VERSION ""

NS_ :

BS_:

BU_: XXX

BO_ 53 ACCELERATOR: 32 XXX
 SG_ CHECKSUM : 0|16@1+ (1,0) [0|65535] "" XXX
 SG_ COUNTER : 16|8@1+ (1,0) [0|255] "" XXX
 SG_ GEAR : 192|3@1+ (1,0) [0|7] "" XXX
 SG_ ACCELERATOR_PEDAL : 40|8@1+ (1,0) [0|255] "" XXX

BO_ 80 LKAS: 16 XXX
 SG_ STEER_REQ : 52|1@1+ (1,0) [0|1] "" XXX
 SG_ TORQUE_REQUEST : 41|11@1+ (1,-1024) [0|4095] "" XXX
 SG_ LKA_ICON : 38|2@1+ (1,0) [0|255] "" XXX
 SG_ NEW_SIGNAL_1 : 27|2@1+ (1,0) [0|255] "" XXX
 SG_ LFA_BUTTON : 56|1@1+ (1,0) [0|255] "" XXX
 SG_ COUNTER : 16|8@1+ (1,0) [0|255] "" XXX
 SG_ CHECKSUM : 0|16@1+ (1,0) [0|65535] "" XXX
 SG_ STEER_MODE : 65|3@1+ (1,0) [0|1] "" XXX
 SG_ LKA_WARNING : 32|1@1+ (1,0) [0|1] "" XXX
 SG_ LKA_ASSIST : 62|1@1+ (1,0) [0|1] "" XXX
 SG_ LKA_MODE : 24|3@1+ (1,0) [0|7] "" XXX
 SG_ NEW_SIGNAL_2 : 70|2@0+ (1,0) [0|3] "" XXX
 SG_ SET_ME_1 : 80|1@0+ (1,0) [0|1] "" XXX
 SG_ NEW_SIGNAL_3 : 111|8@0+ (1,0) [0|255] "" XXX

BO_ 298 LFA: 16 XXX
 SG_ STEER_REQ : 52|1@1+ (1,0) [0|1] "" XXX
 SG_ TORQUE_REQUEST : 41|11@1+ (1,-1024) [0|4095] "" XXX
 SG_ LKA_ICON : 38|2@1+ (1,0) [0|255] "" XXX
 SG_ NEW_SIGNAL_1 : 27|2@1+ (1,0) [0|255] "" XXX
 SG_ LFA_BUTTON : 56|1@1+ (1,0) [0|255] "" XXX
 SG_ COUNTER : 16|8@1+ (1,0) [0|255] "" XXX
 SG_ CHECKSUM : 0|16@1+ (1,0) [0|65535] "" XXX
 SG_ STEER_MODE : 65|3@1+ (1,0) [0|1] "" XXX
 SG_ LKA_WARNING : 32|1@1+ (1,0) [0|1] "" XXX
 SG_ LKA_ASSIST : 62|1@1+ (1,0) [0|1] "" XXX
 SG_ LKA_MODE : 24|3@1+ (1,0) [0|7] "" XXX
 SG_ NEW_SIGNAL_2 : 70|2@0+ (1,0) [0|3] "" XXX
 SG_ SET_ME_1 : 80|1@0+ (1,0) [0|1] "" XXX
 SG_ NEW_SIGNAL_3 : 111|8@0+ (1,0) [0|255] "" XXX

BO_ 96 ESP_STATUS: 32 XXX
 SG_ CHECKSUM : 0|16@1+ (1,0) [0|65535] "" XXX
 SG_ COUNTER : 16|8@1+ (1,0) [0|255] "" XXX
 SG_ ESP_DISABLED : 42|3@1+ (1,0) [0|63] "" XXX

BO_ 101 BRAKE: 32 XXX
 SG_ CHECKSUM : 0|16@1+ (1,0) [0|65535] "" XXX
 SG_ COUNTER : 16|8@1+ (1,0) [0|255] "" XXX
 SG_ BRAKE_PRESSED : 57|1@1+ (1,0) [0|3] "" XXX

BO_ 160 WHEEL_SPEEDS: 24 XXX
 SG_ CHECKSUM : 0|16@1+ (1,0) [0|65535] "" XXX
 SG_ COUNTER : 16|8@1+ (1,0) [0|255] "" XXX
 SG_ WHEEL_SPEED_1 : 64|16@1+ (0.03125,0) [0|65535] "m/s" XXX
 SG_ WHEEL_SPEED_2 : 80|16@1+ (0.03125,0) [0|65535] "m/s" XXX
 SG_ WHEEL_SPEED_3 : 96|16@1+ (0.03125,0) [0|65535] "m/s" XXX
 SG_ WHEEL_SPEED_4 : 112|16@1+ (0.03125,0) [0|65535] "m/s" XXX

BO_ 234 MDPS: 24 XXX
 SG_ CHECKSUM : 0|16@1+ (1,0) [0|65535] "" XXX
 SG_ COUNTER : 16|8@1+ (1,0) [0|255] "" XXX
 SG_ LKA_ACTIVE : 48|1@0+ (1,0) [0|16777215] "" XXX
 SG_ STEERING_OUT_TORQUE : 64|12@1+ (0.1,-204.8) [0|65535] "" XXX
 SG_ STEERING_COL_TORQUE : 80|13@1+ (1,-4095) [0|4095] "" XXX
 SG_ STEERING_ANGLE : 96|16@1- (-0.1,0) [0|255] "deg" XXX
 SG_ STEERING_ANGLE_2 : 128|16@1- (-0.1,0) [0|65535] "deg" XXX

BO_ 293 STEERING_SENSORS: 16 XXX
 SG_ CHECKSUM : 0|16@1+ (1,0) [0|65535] "" XXX
 SG_ COUNTER : 16|8@1+ (1,0) [0|255] "" XXX
 SG_ STEERING_RATE : 40|8@1- (-0.1,0) [0|255] "deg/s" XXX
 SG_ STEERING_ANGLE : 24|16@1- (-0.1,0) [0|255] "deg" XXX

BO_ 373 SCC1: 24 XXX
 SG_ CHECKSUM : 0|16@1+ (1,0) [0|65535] "" XXX
 SG_ COUNTER : 16|8@1+ (1,0) [0|255] "" XXX
 SG_ ACCEL_REQ : 48|13@1- (1,0) [0|1023] "" XXX
 SG_ CRUISE_ACTIVE : 68|1@0+ (1,0) [0|1] "" XXX

BO_ 416 CRUISE_INFO: 32 XXX
 SG_ CHECKSUM : 0|16@1+ (1,0) [0|65535] "" XXX
 SG_ COUNTER : 16|8@1+ (1,0) [0|255] "" XXX
 SG_ CRUISE_STANDSTILL : 76|1@1+ (1,0) [0|1] "" XXX
 SG_ SET_SPEED : 102|7@0+ (1,0) [0|127] "km/h or mph" XXX
 SG_ CRUISE_ACTIVE : 184|1@1+ (1,0) [0|1] "" XXX

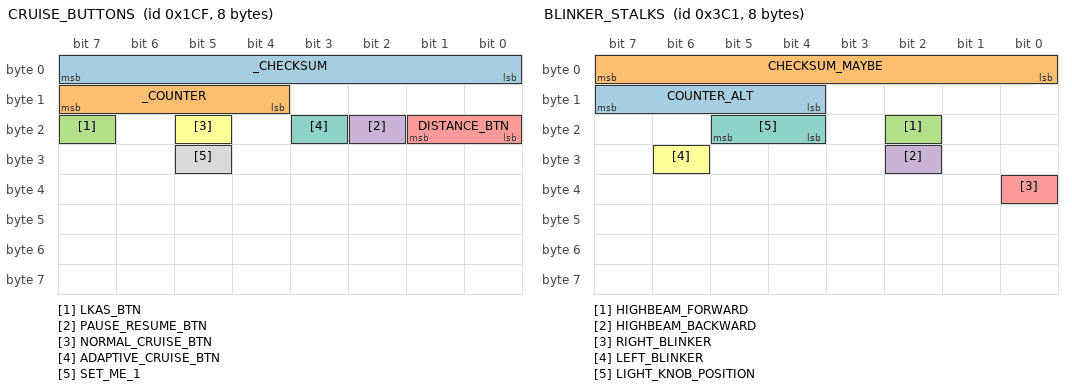
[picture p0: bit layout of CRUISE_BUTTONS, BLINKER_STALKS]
BO_ 463 CRUISE_BUTTONS: 8 XXX
 SG_ _CHECKSUM : 0|8@1+ (1,0) [0|65535] "" XXX
 SG_ _COUNTER : 12|4@1+ (1,0) [0|255] "" XXX
 SG_ LKAS_BTN : 23|1@1+ (1,0) [0|1] "" XXX
 SG_ PAUSE_RESUME_BTN : 18|1@1+ (1,0) [0|1] "" XXX
 SG_ DISTANCE_BTN : 16|2@1+ (1,0) [0|3] "" XXX
 SG_ NORMAL_CRUISE_BTN : 21|1@1+ (1,0) [0|1] "" XXX
 SG_ ADAPTIVE_CRUISE_BTN : 19|1@1+ (1,0) [0|1] "" XXX
 SG_ SET_ME_1 : 29|1@1+ (1,0) [0|1] "" XXX

BO_ 961 BLINKER_STALKS: 8 XXX
 SG_ COUNTER_ALT : 15|4@0+ (1,0) [0|15] "" XXX
 SG_ CHECKSUM_MAYBE : 7|8@0+ (1,0) [0|255] "" XXX
 SG_ HIGHBEAM_FORWARD : 18|1@0+ (1,0) [0|1] "" XXX
 SG_ HIGHBEAM_BACKWARD : 26|1@0+ (1,0) [0|1] "" XXX
 SG_ RIGHT_BLINKER : 32|1@0+ (1,0) [0|1] "" XXX
 SG_ LEFT_BLINKER : 30|1@0+ (1,0) [0|1] "" XXX
 SG_ LIGHT_KNOB_POSITION : 21|2@0+ (1,0) [0|3] "" XXX

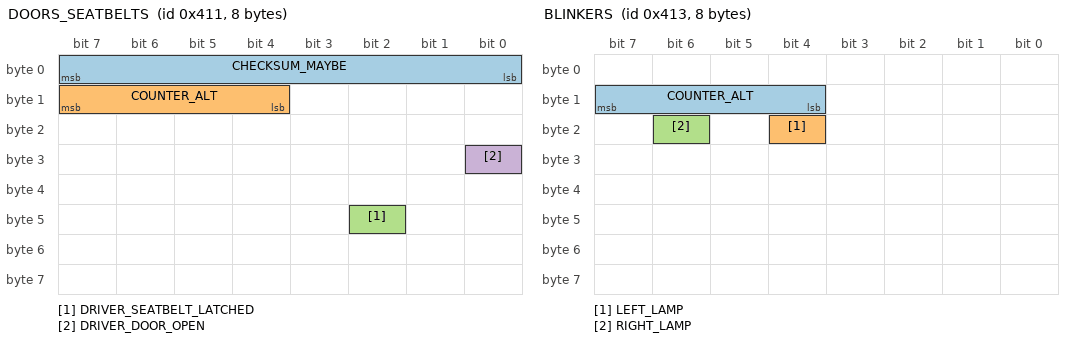
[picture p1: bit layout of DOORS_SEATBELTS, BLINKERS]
BO_ 1041 DOORS_SEATBELTS: 8 XXX
 SG_ CHECKSUM_MAYBE : 7|8@0+ (1,0) [0|65535] "" XXX
 SG_ COUNTER_ALT : 15|4@0+ (1,0) [0|15] "" XXX
 SG_ DRIVER_SEATBELT_LATCHED : 42|1@0+ (1,0) [0|1] "" XXX
 SG_ DRIVER_DOOR_OPEN : 24|1@1+ (1,0) [0|1] "" XXX

BO_ 1043 BLINKERS: 8 XXX
 SG_ COUNTER_ALT : 15|4@0+ (1,0) [0|15] "" XXX
 SG_ LEFT_LAMP : 20|1@0+ (1,0) [0|1] "" XXX
 SG_ RIGHT_LAMP : 22|1@0+ (1,0) [0|1] "" XXX

BO_ 1240 CLUSTER_INFO: 8 XXX
 SG_ DISTANCE_UNIT : 0|1@1+ (1,0) [0|1] "" XXX

BO_ 480 NEW_MSG_1: 16 XXX
 SG_ CHECKSUM : 0|16@1+ (1,0) [0|65535] "" XXX
 SG_ COUNTER : 16|8@1+ (1,0) [0|255] "" XXX
 SG_ LFA_ENABLED : 63|1@0+ (1,0) [0|1] "" XXX

BO_ 81 NEW_MSG_2: 32 XXX
 SG_ NEW_SIGNAL_1 : 71|1@0+ (1,0) [0|1] "" XXX
 SG_ NEW_SIGNAL_2 : 228|1@0+ (1,0) [0|1] "" XXX
 SG_ NEW_SIGNAL_3 : 195|1@0+ (1,0) [0|1] "" XXX
 SG_ NEW_SIGNAL_4 : 0|16@1+ (1,0) [0|65535] "" XXX
 SG_ NEW_SIGNAL_5 : 16|8@1+ (1,0) [0|255] "" XXX

BO_ 389 NEW_MSG_3: 8 XXX
 SG_ NEW_SIGNAL_1 : 28|1@0+ (1,0) [0|1] "" XXX
 SG_ NEW_SIGNAL_2 : 80|16@1+ (1,0) [0|65535] "" XXX
 SG_ NEW_SIGNAL_3 : 96|16@1+ (1,0) [0|65535] "" XXX

BO_ 256 NEW_MSG_6: 32 XXX
 SG_ NEW_SIGNAL_3 : 144|16@1+ (1,0) [0|255] "" XXX
 SG_ NEW_SIGNAL_4 : 160|16@1+ (1,0) [0|65535] "" XXX
 SG_ NEW_SIGNAL_5 : 200|16@1+ (1,0) [0|65535] "" XXX
 SG_ NEW_SIGNAL_1 : 120|16@1+ (1,0) [0|65535] "" XXX

BO_ 111 NEW_MSG_4: 8 XXX

BO_ 64 NEW_MSG_7: 32 XXX
 SG_ NEW_SIGNAL_1 : 128|16@1+ (1,0) [0|65535] "" XXX

BO_ 181 NEW_MSG_5: 32 XXX
 SG_ NEW_SIGNAL_2 : 80|8@1+ (1,0) [0|255] "" XXX
 SG_ NEW_SIGNAL_3 : 176|16@1+ (1,0) [0|65535] "" XXX
 SG_ NEW_SIGNAL_1 : 64|8@1+ (1,0) [0|255] "" XXX
 SG_ NEW_SIGNAL_4 : 200|16@1- (1,0) [0|65535] "" XXX
 SG_ NEW_SIGNAL_5 : 48|8@1+ (1,0) [0|255] "" XXX

BO_ 437 NEW_MSG_8: 32 XXX
 SG_ NEW_SIGNAL_1 : 24|16@1+ (1,0) [0|65535] "" XXX
 SG_ NEW_SIGNAL_3 : 64|16@1+ (1,0) [0|65535] "" XXX
 SG_ NEW_SIGNAL_2 : 40|16@1+ (1,0) [0|65535] "" XXX
 SG_ NEW_SIGNAL_5 : 96|16@1+ (1,0) [0|65535] "" XXX
 SG_ NEW_SIGNAL_4 : 80|16@1+ (1,0) [0|65535] "" XXX
 SG_ NEW_SIGNAL_6 : 112|16@1+ (1,0) [0|65535] "" XXX
 SG_ NEW_SIGNAL_7 : 128|16@1+ (1,0) [0|65535] "" XXX
 SG_ NEW_SIGNAL_8 : 144|16@1+ (1,0) [0|65535] "" XXX
 SG_ NEW_SIGNAL_9 : 200|24@1- (1,0) [0|4294967295] "" XXX
 SG_ NEW_SIGNAL_10 : 192|8@1+ (1,0) [0|255] "" XXX

CM_ SG_ 961 COUNTER_ALT "only increments on change";
CM_ SG_ 1041 COUNTER_ALT "only increments on change";
CM_ SG_ 1043 COUNTER_ALT "only increments on change";
VAL_ 53 GEAR 0 "P" 5 "D" 6 "N" 7 "R" ;
VAL_ 80 LKA_ICON 0 "hidden" 1 "grey" 2 "green" 3 "flashing green" ;
VAL_ 80 LKA_MODE 1 "warning only" 2 "assist" 6 "off" ;
